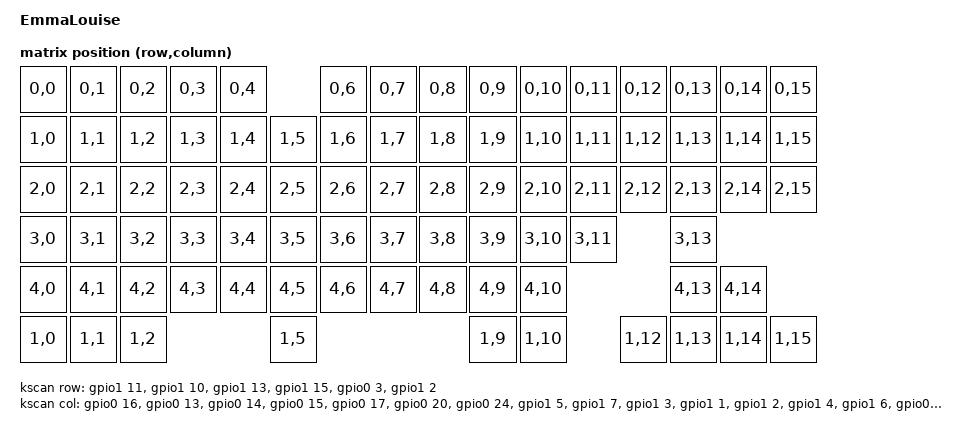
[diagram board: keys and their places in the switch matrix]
// This file was generated from a template. Edit it to match your keyboard.
// See https://docs.zephyrproject.org/4.1.0/hardware/porting/board_porting.html
// and https://zmk.dev/docs/development/hardware-integration/new-shield for more
// instructions.

/dts-v1/;
#include <nordic/nrf52840_qiaa.dtsi>
#include <dt-bindings/zmk/matrix_transform.h>

#include "emmalouise-pinctrl.dtsi"
#include "emmalouise-layouts.dtsi"

/ {
    model = "EmmaLouise";
    compatible = "emmalouise";

    chosen {
        zephyr,code-partition = &code_partition;
        zephyr,sram = &sram0;
        zephyr,flash = &flash0;
        // Uncomment this if you enabled one of the "vddh" nodes below.
        zmk,battery = &vbatt; //double check
        zmk,physical-layout = &default_layout;
        zmk,backlight = &backlight;
    };

    backlight: pwmleds {
        compatible = "pwm-leds";
        pwm_led_0 {
            pwms = <&pwm0 0 PWM_MSEC(10) PWM_POLARITY_NORMAL>;
        };
    };

    kscan: kscan {
        // If the hardware does not use a switch matrix, change this to the
        // appropriate driver and update the properties below to match.
        // See https://zmk.dev/docs/config/kscan for supported key scan drivers.
        compatible = "zmk,kscan-gpio-matrix";
        // Set this to "col2row" or "row2col" to match the hardware. If using
        // "row2col", change the col-gpios to (GPIO_ACTIVE_HIGH | GPIO_PULL_DOWN)
        // and the row-gpios to GPIO_ACTIVE_HIGH.
        diode-direction = "row2col";
        wakeup-source;

        // Replace these comments with the GPIO pins in the matrix.
        // See https://zmk.dev/docs/development/hardware-integration/new-shield#shield-overlays
        col-gpios
            = <&gpio0 16 GPIO_ACTIVE_HIGH>
            , <&gpio0 13 GPIO_ACTIVE_HIGH>
            , <&gpio0 14 GPIO_ACTIVE_HIGH>
            , <&gpio0 15 GPIO_ACTIVE_HIGH>
            , <&gpio0 17 GPIO_ACTIVE_HIGH>
            , <&gpio0 20 GPIO_ACTIVE_HIGH>
            , <&gpio0 24 GPIO_ACTIVE_HIGH>
            , <&gpio1 5 GPIO_ACTIVE_HIGH>
            , <&gpio1 7 GPIO_ACTIVE_HIGH>
            , <&gpio1 3 GPIO_ACTIVE_HIGH>
            , <&gpio1 1 GPIO_ACTIVE_HIGH>
            , <&gpio1 2 GPIO_ACTIVE_HIGH>
            , <&gpio1 4 GPIO_ACTIVE_HIGH>
            , <&gpio1 6 GPIO_ACTIVE_HIGH>
            , <&gpio0 9 GPIO_ACTIVE_HIGH>
            , <&gpio0 10 GPIO_ACTIVE_HIGH>
            ;

        row-gpios
            = <&gpio1 11 (GPIO_ACTIVE_HIGH | GPIO_PULL_DOWN)>
            , <&gpio1 10 (GPIO_ACTIVE_HIGH | GPIO_PULL_DOWN)>
            , <&gpio1 13 (GPIO_ACTIVE_HIGH | GPIO_PULL_DOWN)>
            , <&gpio1 15 (GPIO_ACTIVE_HIGH | GPIO_PULL_DOWN)>
            , <&gpio0 3 (GPIO_ACTIVE_HIGH | GPIO_PULL_DOWN)>
            , <&gpio1 2 (GPIO_ACTIVE_HIGH | GPIO_PULL_DOWN)>
            ;
    };

    default_transform: default_transform {
        // See https://zmk.dev/docs/development/hardware-integration/new-shield#matrix-transform
        // for how to configure this
        compatible = "zmk,matrix-transform";
        columns = <16>;
        rows = <6>;

        map = <
            RC(0, 0) RC(0, 1) RC(0, 2) RC(0, 3) RC(0, 4)          RC(0, 6) RC(0, 7) RC(0, 8) RC(0, 9) RC(0, 10) RC(0, 11) RC(0, 12) RC(0, 13) RC(0, 14) RC(0, 15)
            RC(1, 0) RC(1, 1) RC(1, 2) RC(1, 3) RC(1, 4) RC(1, 5) RC(1, 6) RC(1, 7) RC(1, 8) RC(1, 9) RC(1, 10) RC(1, 11) RC(1, 12) RC(1, 13) RC(1, 14) RC(1, 15)
            RC(2, 0) RC(2, 1) RC(2, 2) RC(2, 3) RC(2, 4) RC(2, 5) RC(2, 6) RC(2, 7) RC(2, 8) RC(2, 9) RC(2, 10) RC(2, 11) RC(2, 12) RC(2, 13) RC(2, 14) RC(2, 15)
            RC(3, 0) RC(3, 1) RC(3, 2) RC(3, 3) RC(3, 4) RC(3, 5) RC(3, 6) RC(3, 7) RC(3, 8) RC(3, 9) RC(3, 10) RC(3, 11)           RC(3, 13)
            RC(4, 0) RC(4, 1) RC(4, 2) RC(4, 3) RC(4, 4) RC(4, 5) RC(4, 6) RC(4, 7) RC(4, 8) RC(4, 9) RC(4, 10)                     RC(4, 13) RC(4, 14)
            RC(1, 0) RC(1, 1) RC(1, 2)                   RC(1, 5)                            RC(1, 9) RC(1, 10)           RC(1, 12) RC(1, 13) RC(1, 14) RC(1, 15)
        >;
    };

    leds {
        compatible = "gpio-leds";

        // If you have a GPIO routed to a status LED, set it here.
        // Otherwise, delete this block.
        green_led: led_0 {
            gpios = <&gpio0 19 GPIO_ACTIVE_HIGH>;
        };
        red_led: led_1 {
            gpios = <&gpio0 21 GPIO_ACTIVE_HIGH>;
        };
        caps_led: led_3 {
            gpios = <&gpio0 22 GPIO_ACTIVE_HIGH>;
        };
    };

    pwm_default {
        backlight_led: led_2 {
            gpios = <&gpio1 0 GPIO_ACTIVE_HIGH>;
        };
    };

    pwm0_default: pwm0_default {
        group1 {
            psels = <NRF_PSEL(PWM_OUT0, 1, 0)>;
        };
    };

    pwm0_sleep: pwm0_sleep {
        group1 {
            psels = <NRF_PSEL(PWM_OUT0, 1, 0)>;
            low-power-enable;
        };
    };

    vbatt: vbatt {
        compatible = "voltage-divider";
        io-channels = <&adc 7>;
        output-ohms = <100000>;
        full-ohms = <(100000 + 100000)>;
    };
};

&adc {
    status = "okay";
};

&gpiote {
    status = "okay";
};

&gpio0 {
    status = "okay";
};

&gpio1 {
    status = "okay";
};

&uart0 {
    compatible = "nordic,nrf-uarte";
    current-speed = <115200>;
    pinctrl-0 = <&uart0_default>;
    pinctrl-1 = <&uart0_sleep>;
    pinctrl-names = "default", "sleep";
};

&pwm0 {
    status = "okay";
    pinctrl-0 = <&pwm0_default>;
    pinctrl-1 = <&pwm0_sleep>;
    pinctrl-names = "default", "sleep";
};

// If you use the NFC pins as GPIOs, uncomment this. Otherwise, remove it.
// &uicr {
//     nfct-pins-as-gpios;
// };

zephyr_udc0: &usbd {
    status = "okay";
};

&flash0 {
    // Adjust this flash map as is necessary for your board. For more information, see
    // https://docs.zephyrproject.org/4.1.0/services/storage/flash_map/flash_map.html#relationship-with-devicetree
    partitions {
        compatible = "fixed-partitions";
        #address-cells = <1>;
        #size-cells = <1>;

        code_partition: partition@1000 {
            reg = <DT_SIZE_K(4) DT_SIZE_K(844)>;
        };

        // If using a bootloader with SoftDevice included, replace the code_partition
        // node above with the following. If using SoftDevice v7, change 26000 to 27000.

        // sd_partition: partition@0 {
        //     reg = <0x0 <DT_SIZE_K(4)>;
        // };
        // code_partition: partition@26000 {
        //     reg = <DT_SIZE_K(152) DT_SIZE_K(792)>;
        // };

        // The flash starting at 0x000d4000 and ending at
        // 0x000f3fff is reserved for use by the application.

        // Storage partition will be used by NVS if enabled.
        storage_partition: partition@d4000 {
            reg = <DT_SIZE_K(848) DT_SIZE_K(128)>;
        };

        boot_partition: partition@f4000 {
            reg = <DT_SIZE_K(976) DT_SIZE_K(48)>;
        };
    };
};
